AUTOSAR XML (schema 4-3-0)
package /Impl_SWC_VES_ARPkg
  swc implementation Impl_SWC_VES_type: programming-language=C, sw-version=1.0.0, vendor-id=0, behavior=SWC_VES_type_IB
    code-descriptors:
      code SRC: artifact-descriptors=autosar-engineering-object={short-label=EngObject, category=SWSRC}
    resource consumption ResourceConsumption
      memory section Mem_SWC_VES_CODE: size=0, sw-addrmethod=CODE, symbol=CODE
package /SWC_VES_ARPkg
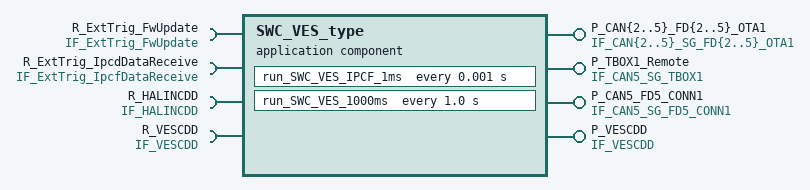
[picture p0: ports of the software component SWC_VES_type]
  application sw component type SWC_VES_type
    7 x provide port:
      P_CAN{2..5}_FD{2..5}_OTA1: provided-interface=IF_CAN{2..5}_SG_FD{2..5}_OTA1
      P_TBOX1_Remote: provided-interface=IF_CAN5_SG_TBOX1
      P_CAN5_FD5_CONN1: provided-interface=IF_CAN5_SG_FD5_CONN1
      P_VESCDD: provided-interface=IF_VESCDD
    4 x require port:
      R_ExtTrig_FwUpdate: required-interface=IF_ExtTrig_FwUpdate
      R_ExtTrig_IpcdDataReceive: required-interface=IF_ExtTrig_IpcfDataReceive
      R_HALINCDD: required-interface=IF_HALINCDD
      R_VESCDD: required-interface=IF_VESCDD
    behavior SWC_VES_type_IB: handle-termination-and-restart=NO-SUPPORT, port-api-option{enable-take-address=false, indirect-api=false, port=P_VESCDD}
      external trigger occurred event ETE_FwUpdateEvent: start-on-event=run_Trig_FwUpdate, trigger=R_ExtTrig_FwUpdate.Trig_FwUpdateEvent
      external trigger occurred event ETE_IpcfDataReceive: start-on-event=run_Trig_IpcfDataReceive, trigger=R_ExtTrig_IpcdDataReceive.Trig_IpcfDataReceiveEvent
      timing event TE_IPCF_1ms: start-on-event=run_SWC_VES_IPCF_1ms, period=0.001
      timing event TE_VES_1000ms: start-on-event=run_SWC_VES_1000ms, period=1.0
      operation invoked event oie_P_VESCDD_CSOP_FrameRawData: start-on-event=run_VESCDD, operation=P_VESCDD.CSOP_FrameRawData
      5 x runnable:
        run_SWC_VES_1000ms
        run_SWC_VES_IPCF_1ms
          sync call scp_CSOP_IPCF_Handler: operation=R_HALINCDD.CSOP_IPCF_Handler, timeout=0.0
        run_Trig_FwUpdate
        run_Trig_IpcfDataReceive
          data-send-points:
            6 x access:
              dsp_CAN{2..5}_SG_FD{2..5}_OTA1: accessed-variable=P_CAN{2..5}_FD{2..5}_OTA1.CAN{2..5}_SG_FD{2..5}_OTA1
              dsp_CAN5_SG_TBOX1: accessed-variable=P_TBOX1_Remote.CAN5_SG_TBOX1
              dsp_CAN5_SG_FD5_CONN1: accessed-variable=P_CAN5_FD5_CONN1.CAN5_SG_FD5_CONN1
          sync call scp_CSOP_FrameRawData: operation=R_VESCDD.CSOP_FrameRawData, timeout=0.0
        run_VESCDD
